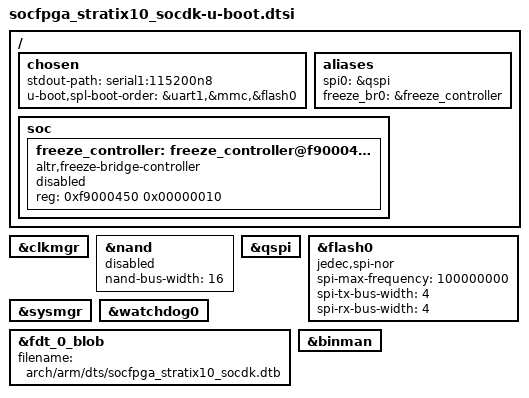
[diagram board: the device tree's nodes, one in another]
// SPDX-License-Identifier: GPL-2.0+
/*
 * U-Boot additions
 *
 * Copyright (C) 2019-2022 Intel Corporation <www.intel.com>
 */

#include "socfpga_stratix10-u-boot.dtsi"

/{
	chosen {
		stdout-path = "serial1:115200n8";
		u-boot,spl-boot-order = &uart1,&mmc,&flash0;
	};

	aliases {
		spi0 = &qspi;
		freeze_br0 = &freeze_controller;
	};

	soc {
		freeze_controller: freeze_controller@f9000450 {
			compatible = "altr,freeze-bridge-controller";
			reg = <0xf9000450 0x00000010>;
			status = "disabled";
		};
	};
};

&clkmgr {
	bootph-all;
};

&nand {
	status = "disabled";
	nand-bus-width = <16>;
	bootph-all;
};

&qspi {
	status = "okay";
	bootph-all;
};

&flash0 {
	compatible = "jedec,spi-nor";
	spi-max-frequency = <100000000>;
	spi-tx-bus-width = <4>;
	spi-rx-bus-width = <4>;
	bootph-all;
	/delete-property/ cdns,read-delay;
};

&sysmgr {
	bootph-all;
};

&watchdog0 {
	status = "okay";
	bootph-all;
};

&fdt_0_blob {
	filename = "arch/arm/dts/socfpga_stratix10_socdk.dtb";
};

&binman {
	/delete-node/ kernel;
};
